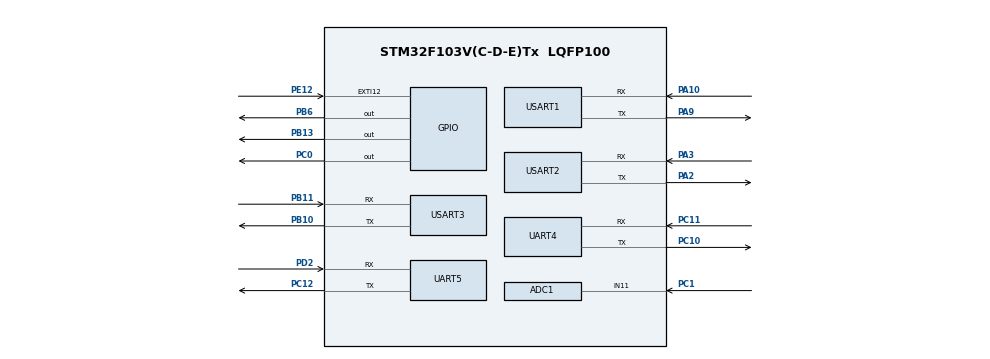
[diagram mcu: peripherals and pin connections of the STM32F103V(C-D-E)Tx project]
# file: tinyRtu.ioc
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ADC1.Channel-0\#ChannelRegularConversion=ADC_CHANNEL_11
ADC1.Channel-3\#ChannelRegularConversion=ADC_CHANNEL_TEMPSENSOR
ADC1.DiscontinuousConvMode=ENABLE
ADC1.NbrOfConversion=2
ADC1.NbrOfConversionFlag=1
ADC1.Rank-0\#ChannelRegularConversion=1
ADC1.Rank-3\#ChannelRegularConversion=2
ADC1.SamplingTime-0\#ChannelRegularConversion=ADC_SAMPLETIME_1CYCLE_5
ADC1.SamplingTime-3\#ChannelRegularConversion=ADC_SAMPLETIME_1CYCLE_5
ADC1.master=1
Mcu.Family=STM32F1
Mcu.Name=STM32F103V(C-D-E)Tx
Mcu.Package=LQFP100
NVIC.EXTI15_10_IRQn=true\:1\:0\:true\:false\:true\:true
NVIC.PriorityGroup=NVIC_PRIORITYGROUP_4
NVIC.RTC_Alarm_IRQn=true\:0\:0\:false\:false\:true\:true
NVIC.RTC_IRQn=true\:0\:0\:false\:false\:true\:true
OSC_IN.Mode=HSE-External-Oscillator
OSC_IN.Signal=RCC_OSC_IN
OSC_OUT.Mode=HSE-External-Oscillator
OSC_OUT.Signal=RCC_OSC_OUT
PA10.Mode=Asynchronous
PA10.Signal=USART1_RX
PA13.Mode=Serial_Wire
PA13.Signal=SYS_JTMS-SWDIO
PA14.Mode=Serial_Wire
PA14.Signal=SYS_JTCK-SWCLK
PA2.Mode=Asynchronous
PA2.Signal=USART2_TX
PA3.Mode=Asynchronous
PA3.Signal=USART2_RX
PA9.Mode=Asynchronous
PA9.Signal=USART1_TX
PB10.Mode=Asynchronous
PB10.Signal=USART3_TX
PB11.Mode=Asynchronous
PB11.Signal=USART3_RX
PB13.GPIO_ModeDefaultOutputPP=GPIO_MODE_OUTPUT_OD
PB13.GPIO_Speed=GPIO_SPEED_FREQ_LOW
PB13.PinState=GPIO_PIN_RESET
PB13.Signal=GPIO_Output
PB6.Signal=GPIO_Output
PC0.Signal=GPIO_Output
PC1.Signal=ADCx_IN11
PC10.Mode=Asynchronous
PC10.Signal=UART4_TX
PC11.Mode=Asynchronous
PC11.Signal=UART4_RX
PC12.Mode=Asynchronous
PC12.Signal=UART5_TX
PC14-OSC32_IN.Mode=LSE-External-Oscillator
PC14-OSC32_IN.Signal=RCC_OSC32_IN
PC15-OSC32_OUT.Mode=LSE-External-Oscillator
PC15-OSC32_OUT.Signal=RCC_OSC32_OUT
PD2.Mode=Asynchronous
PD2.Signal=UART5_RX
PE12.GPIO_ModeDefaultEXTI=GPIO_MODE_IT_FALLING
PE12.GPIO_PuPd=GPIO_NOPULL
PE12.Signal=GPXTI12
ProjectManager.HeapSize=0x600
ProjectManager.StackSize=0x800
ProjectManager.TargetToolchain=TrueSTUDIO
RCC.APB1Freq_Value=8000000
RCC.APB2Freq_Value=8000000
RCC.PLLSourceVirtual=RCC_PLLSOURCE_HSE
RCC.RTCClockSelection=RCC_RTCCLKSOURCE_LSE
RCC.SYSCLKSource=RCC_SYSCLKSOURCE_HSE
RCC.USBFreq_Value=16000000
SH.ADCx_IN11.0=ADC1_IN11,IN11
TIM2.AutoReloadPreload=TIM_AUTORELOAD_PRELOAD_DISABLE
TIM2.Period=65535
TIM2.Prescaler=7
UART4.VirtualMode=Asynchronous
UART5.VirtualMode=Asynchronous
USART1.VirtualMode=VM_ASYNC
USART2.VirtualMode=VM_ASYNC
USART3.VirtualMode=VM_ASYNC
VP_ADC1_TempSens_Input.Mode=IN-TempSens
VP_RTC_No_RTC_Output.Mode=RTC_OUT_NO
VP_RTC_VS_RTC_Activate.Mode=RTC_Enabled
VP_RTC_VS_RTC_Calendar.Mode=RTC_Calendar
VP_TIM2_VS_ClockSourceINT.Mode=Internal
VP_TIM2_VS_ClockSourceITR.Mode=TriggerSource_ITR0
VP_TIM2_VS_ControllerModeTrigger.Mode=Trigger Mode
board=tinyRtu

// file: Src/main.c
/**
  ******************************************************************************
  * File Name          : main.c
  * Description        : Main program body
  ******************************************************************************
  ** This notice applies to any and all portions of this file
  * that are not between comment pairs USER CODE BEGIN and
  * USER CODE END. Other portions of this file, whether
  * inserted by the user or by software development tools
  * are owned by their respective copyright owners.
  *
  * COPYRIGHT(c) 2017 STMicroelectronics
  *
  * Redistribution and use in source and binary forms, with or without modification,
  * are permitted provided that the following conditions are met:
  *   1. Redistributions of source code must retain the above copyright notice,
  *      this list of conditions and the following disclaimer.
  *   2. Redistributions in binary form must reproduce the above copyright notice,
  *      this list of conditions and the following disclaimer in the documentation
  *      and/or other materials provided with the distribution.
  *   3. Neither the name of STMicroelectronics nor the names of its contributors
  *      may be used to endorse or promote products derived from this software
  *      without specific prior written permission.
  *
  * THIS SOFTWARE IS PROVIDED BY THE COPYRIGHT HOLDERS AND CONTRIBUTORS "AS IS"
  * AND ANY EXPRESS OR IMPLIED WARRANTIES, INCLUDING, BUT NOT LIMITED TO, THE
  * IMPLIED WARRANTIES OF MERCHANTABILITY AND FITNESS FOR A PARTICULAR PURPOSE ARE
  * DISCLAIMED. IN NO EVENT SHALL THE COPYRIGHT HOLDER OR CONTRIBUTORS BE LIABLE
  * FOR ANY DIRECT, INDIRECT, INCIDENTAL, SPECIAL, EXEMPLARY, OR CONSEQUENTIAL
  * DAMAGES (INCLUDING, BUT NOT LIMITED TO, PROCUREMENT OF SUBSTITUTE GOODS OR
  * SERVICES; LOSS OF USE, DATA, OR PROFITS; OR BUSINESS INTERRUPTION) HOWEVER
  * CAUSED AND ON ANY THEORY OF LIABILITY, WHETHER IN CONTRACT, STRICT LIABILITY,
  * OR TORT (INCLUDING NEGLIGENCE OR OTHERWISE) ARISING IN ANY WAY OUT OF THE USE
  * OF THIS SOFTWARE, EVEN IF ADVISED OF THE POSSIBILITY OF SUCH DAMAGE.
  *
  ******************************************************************************
  */
#include "main.h"
#include "stm32f1xx_hal.h"
#include "adc.h"
#include "rtc.h"
#include "tim.h"
#include "usart.h"
#include "gpio.h"

/* USER CODE BEGIN Includes */
#include "include.h"

/* USER CODE END Includes */

/* USER CODE BEGIN PV */
/* Private variables ---------------------------------------------------------*/
/*水情信息数据*/
waterInf_t waterInf;
/*系统的所有配置数据*/
rtuParameter_t rtuParameter;

/* USER CODE END PV */

void SystemClock_Config(void);

/* USER CODE BEGIN PFP */
/* Private function prototypes -----------------------------------------------*/

/* USER CODE END PFP */

int main(void)
{

  /* MCU Configuration----------------------------------------------------------*/

  /* Reset of all peripherals, Initializes the Flash interface and the Systick. */
  HAL_Init();

  /* Configure the system clock */
  SystemClock_Config();

  /* Initialize all configured peripherals */
  MX_GPIO_Init();
  MX_RTC_Init();
  MX_USART3_UART_Init();
  MX_USART2_UART_Init();
  MX_USART1_UART_Init();
  MX_UART5_Init();
  MX_UART4_Init();
  MX_TIM2_Init();
  MX_ADC1_Init();

  /* USER CODE BEGIN 2 */
  APP_ADC_getTemperature(5);
  APP_PWR_stopMode();
  /* USER CODE END 2 */

  /* Infinite loop */
	while (1) {

	}

}

/** System Clock Configuration
*/
void SystemClock_Config(void)
{

  RCC_OscInitTypeDef RCC_OscInitStruct;
  RCC_ClkInitTypeDef RCC_ClkInitStruct;
  RCC_PeriphCLKInitTypeDef PeriphClkInit;

    /**Initializes the CPU, AHB and APB busses clocks
    */
  RCC_OscInitStruct.OscillatorType = RCC_OSCILLATORTYPE_HSE|RCC_OSCILLATORTYPE_LSE;
  RCC_OscInitStruct.HSEState = RCC_HSE_ON;
  RCC_OscInitStruct.LSEState = RCC_LSE_ON;
  RCC_OscInitStruct.PLL.PLLState = RCC_PLL_NONE;
  if (HAL_RCC_OscConfig(&RCC_OscInitStruct) != HAL_OK)
  {
    _Error_Handler(__FILE__, __LINE__);
  }

    /**Initializes the CPU, AHB and APB busses clocks
    */
  RCC_ClkInitStruct.ClockType = RCC_CLOCKTYPE_HCLK|RCC_CLOCKTYPE_SYSCLK
                              |RCC_CLOCKTYPE_PCLK1|RCC_CLOCKTYPE_PCLK2;
  RCC_ClkInitStruct.SYSCLKSource = RCC_SYSCLKSOURCE_HSE;
  RCC_ClkInitStruct.AHBCLKDivider = RCC_SYSCLK_DIV1;
  RCC_ClkInitStruct.APB1CLKDivider = RCC_HCLK_DIV1;
  RCC_ClkInitStruct.APB2CLKDivider = RCC_HCLK_DIV1;

  if (HAL_RCC_ClockConfig(&RCC_ClkInitStruct, FLASH_LATENCY_0) != HAL_OK)
  {
    _Error_Handler(__FILE__, __LINE__);
  }

  PeriphClkInit.PeriphClockSelection = RCC_PERIPHCLK_RTC|RCC_PERIPHCLK_ADC;
  PeriphClkInit.RTCClockSelection = RCC_RTCCLKSOURCE_LSE;
  PeriphClkInit.AdcClockSelection = RCC_ADCPCLK2_DIV2;
  if (HAL_RCCEx_PeriphCLKConfig(&PeriphClkInit) != HAL_OK)
  {
    _Error_Handler(__FILE__, __LINE__);
  }

    /**Configure the Systick interrupt time
    */
  HAL_SYSTICK_Config(HAL_RCC_GetHCLKFreq()/1000);

    /**Configure the Systick
    */
  HAL_SYSTICK_CLKSourceConfig(SYSTICK_CLKSOURCE_HCLK);

  /* SysTick_IRQn interrupt configuration */
  HAL_NVIC_SetPriority(SysTick_IRQn, 0, 0);
}

/* USER CODE BEGIN 4 */
/*外部中断回调 ：雨量计用*/
void HAL_GPIO_EXTI_Callback(uint16_t GPIO_Pin){
	if (GPIO_Pin == RAINFALL_PIN){
		trigger_rain_signal(&waterInf);
	}
}

/* USER CODE END 4 */

void _Error_Handler(char * file, int line)
{
	while (1) {
	}
}

#ifdef USE_FULL_ASSERT

/**
   * @brief Reports the name of the source file and the source line number
   * where the assert_param error has occurred.
   * @param file: pointer to the source file name
   * @param line: assert_param error line source number
   * @retval None
   */
void assert_failed(uint8_t* file, uint32_t line)
{
  /* USER CODE BEGIN 6 */
	/* User can add his own implementation to report the file name and line number,
	 ex: printf("Wrong parameters value: file %s on line %d\r\n", file, line) */
	while(1){
	__NOP();
	__NOP();
	}
  /* USER CODE END 6 */

}

#endif

/************************ (C) COPYRIGHT STMicroelectronics *****END OF FILE****/
